# ASR6601 register map
Vendor: ASR Microelectronics; Series: ASR6601; File version: 1.1
CPU: CM4 r0p1, little endian, no MPU, FPU, VTOR, 3 interrupt priority bits
Registers are 32-bit, read-write, no defined reset value unless marked. A register's access mark holds for its fields unless they carry their own. Offsets are from the block's base; [hi:lo] are bit positions; {n}, {i} and the like mark numbered series; 'fields as' and 'values as' point back to an identical list.

## UART0
Base 0x40003000
Same registers: UART1 0x40004000, UART2 0x40010000, UART3 0x40011000
0x00 DR — data register
0x04 RSC_ECR — receive status register / error clear register
0x18 FR ro — flag register
0x20 ILPR — IRDA low power counter register
0x24 IBRD — integer baudrate register
0x28 FBRD — fractional baudrate register
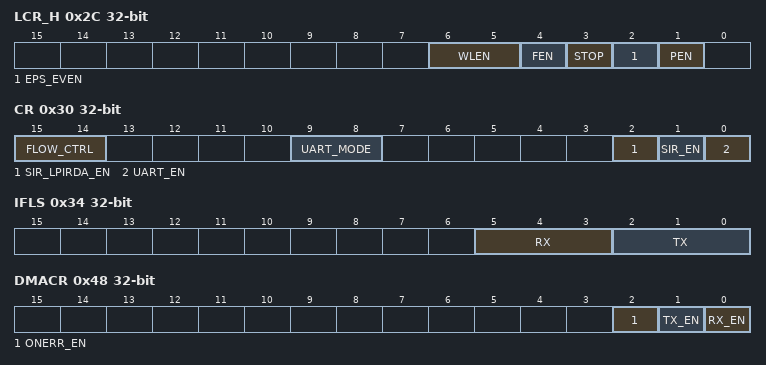
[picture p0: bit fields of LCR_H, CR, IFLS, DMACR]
0x2C LCR_H — line control register
  [6:5] WLEN
    {v}=VALUE_{v+5} (v=0..3)
  [4] FEN
  [3] STOP
    0=VALUE_1; 1=VALUE_2
  [2] EPS_EVEN
  [1] PEN
0x30 CR — control register
  [15:14] FLOW_CTRL
    2=CTS; 3=CTS_RTS; 0=NONE; 1=RTS
  [9:8] UART_MODE
    0=NONE; 2=RX; 1=TX; 3=TXRX
  [2] SIR_LPIRDA_EN
  [1] SIR_EN
  [0] UART_EN
0x34 IFLS — interrupt fifo level select register
  [5:3] RX
    2=VALUE_1_2; 1=VALUE_1_4; 0=VALUE_1_8; 3=VALUE_3_4; 4=VALUE_7_8
  [2:0] TX
    values as RX
0x38 IMSC — interrupt mask set/clear register
0x3C RIS ro — raw interrupt status register
0x40 MIS ro — masked interrupt status register
0x44 ICR wo — interrupt clear register
0x48 DMACR — DMA control register
  [2] ONERR_EN, [1] TX_EN, [0] RX_EN
{0xFE0+4i} ID{i} (i=0..7) ro — ID registers

## LPUART — Low-power UART
Base 0x40005000
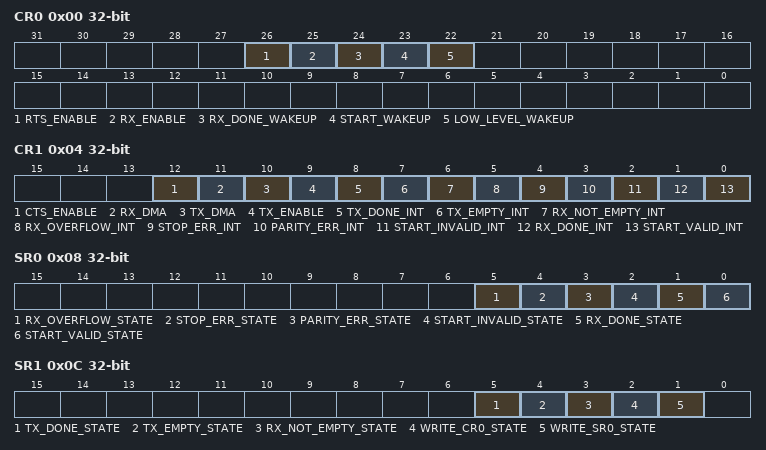
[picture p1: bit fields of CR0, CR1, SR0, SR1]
0x00 CR0 — control register 0
  [26] RTS_ENABLE, [25] RX_ENABLE, [24] RX_DONE_WAKEUP, [23] START_WAKEUP, [22] LOW_LEVEL_WAKEUP
0x04 CR1 — control register 1
  [12] CTS_ENABLE, [11] RX_DMA, [10] TX_DMA, [9] TX_ENABLE, [8] TX_DONE_INT, [7] TX_EMPTY_INT, [6] RX_NOT_EMPTY_INT, [5] RX_OVERFLOW_INT, [4] STOP_ERR_INT, [3] PARITY_ERR_INT, [2] START_INVALID_INT, [1] RX_DONE_INT, [0] START_VALID_INT
0x08 SR0 — status register 0
  [5] RX_OVERFLOW_STATE, [4] STOP_ERR_STATE, [3] PARITY_ERR_STATE, [2] START_INVALID_STATE, [1] RX_DONE_STATE, [0] START_VALID_STATE
0x0C SR1 — status register 1
  [5] TX_DONE_STATE, [4] TX_EMPTY_STATE, [3] RX_NOT_EMPTY_STATE, [2] WRITE_CR0_STATE, [1] WRITE_SR0_STATE
0x10 DATA

## SSP0
Base 0x40006000
Same registers: SSP1 0x40012000, SSP2 0x40013000
0x00 CR0 — control register 0
0x04 CR1 — control register 1
0x08 DR — data register
0x0C SR ro — status register
0x10 CPSR — clock prescale register
0x14 IMSC — interrupt mask set or clear register
0x18 RIS ro — raw interrupt status register
0x1C MIS ro — masked interrupt status register
0x20 ICR — interrupt clear register
0x24 DMA_CR — DMA control register
{0xFE0+4i} PERIPH_ID{i} ro (i=0..3) — peripheral identification register {i}
{0xFF0+4i} PCELL_ID{i} ro (i=0..3) — prime cell identification register {i}

## I2C0
Base 0x40007000
Same registers: I2C1 0x40014000, I2C2 0x40015000
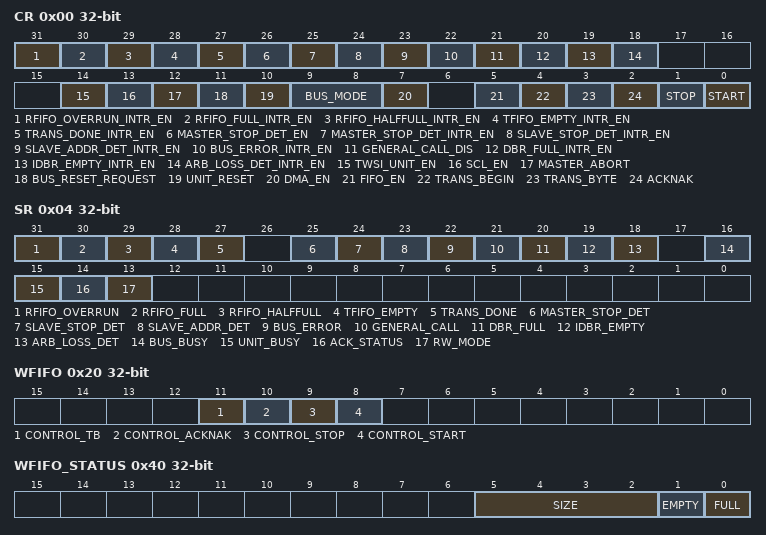
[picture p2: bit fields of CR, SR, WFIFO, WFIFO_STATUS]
0x00 CR — control register
  [31] RFIFO_OVERRUN_INTR_EN
  [30] RFIFO_FULL_INTR_EN
  [29] RFIFO_HALFFULL_INTR_EN
  [28] TFIFO_EMPTY_INTR_EN
  [27] TRANS_DONE_INTR_EN
  [26] MASTER_STOP_DET_EN
  [25] MASTER_STOP_DET_INTR_EN
  [24] SLAVE_STOP_DET_INTR_EN
  [23] SLAVE_ADDR_DET_INTR_EN
  [22] BUS_ERROR_INTR_EN
  [21] GENERAL_CALL_DIS
  [20] DBR_FULL_INTR_EN
  [19] IDBR_EMPTY_INTR_EN
  [18] ARB_LOSS_DET_INTR_EN
  [14] TWSI_UNIT_EN
  [13] SCL_EN
  [12] MASTER_ABORT
  [11] BUS_RESET_REQUEST
  [10] UNIT_RESET
  [9:8] BUS_MODE
    1=FAST; 2=HIGH; 0=STANDARD
  [7] DMA_EN
  [5] FIFO_EN
  [4] TRANS_BEGIN
  [3] TRANS_BYTE
  [2] ACKNAK
  [1] STOP
  [0] START
0x04 SR — status register
  [31] RFIFO_OVERRUN, [30] RFIFO_FULL, [29] RFIFO_HALFFULL, [28] TFIFO_EMPTY, [27] TRANS_DONE, [25] MASTER_STOP_DET, [24] SLAVE_STOP_DET, [23] SLAVE_ADDR_DET, [22] BUS_ERROR, [21] GENERAL_CALL, [20] DBR_FULL, [19] IDBR_EMPTY, [18] ARB_LOSS_DET, [16] BUS_BUSY, [15] UNIT_BUSY, [14] ACK_STATUS, [13] RW_MODE
0x08 SAR — slave address register
0x0C DBR — data buffer register
0x10 LCR — load count register
0x14 WCR — wait count register
0x18 RST_CYCL — reset cycle register
0x1C BMR ro — bus monitor register
0x20 WFIFO — write fifo register
  [11] CONTROL_TB, [10] CONTROL_ACKNAK, [9] CONTROL_STOP, [8] CONTROL_START
0x24 WFIFO_WPTR — write fifo write pointer register
0x28 WFIFO_RPTR — write fifo read pointer register
0x2C RFIFO — read fifo register
0x30 RFIFO_WPTR — read fifo write pointer register
0x34 RFIFO_RPTR — read fifo read pointer register
0x40 WFIFO_STATUS ro — write fifo status register
  [5:2] SIZE, [1] EMPTY, [0] FULL
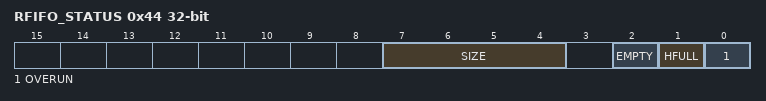
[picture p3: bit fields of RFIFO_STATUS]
0x44 RFIFO_STATUS ro — read fifo status register
  [7:4] SIZE, [2] EMPTY, [1] HFULL, [0] OVERUN
